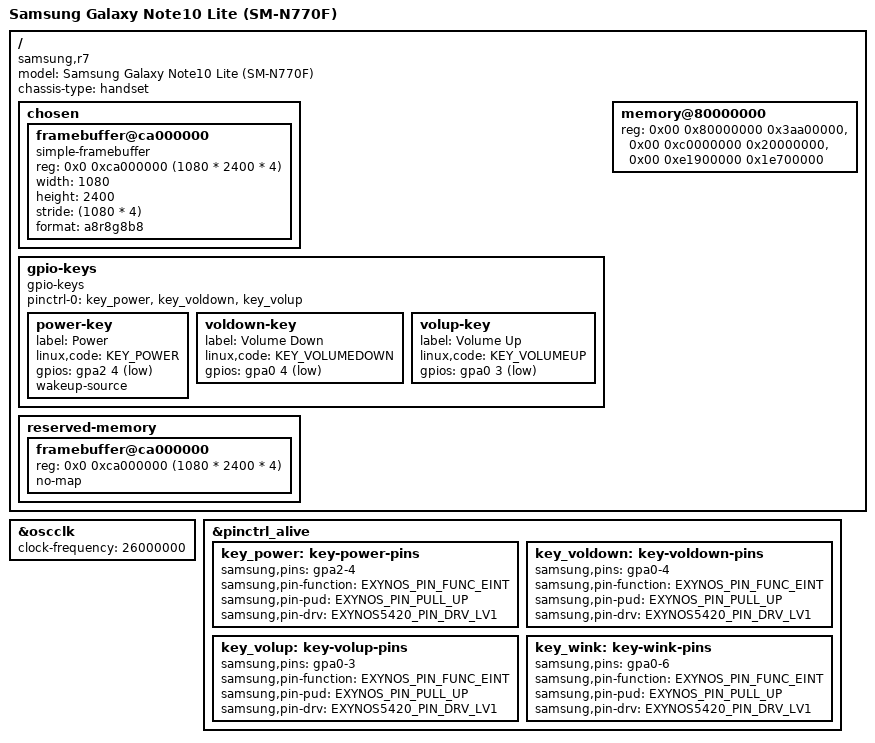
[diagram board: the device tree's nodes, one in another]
// SPDX-License-Identifier: GPL-2.0 OR BSD-3-Clause
/*
 * Samsung Galaxy Note10 Lite (r7/N770F) device tree source
 *
 * Copyright (c) 2024 Markuss Broks <markuss.broks@gmail.com>
 * Copyright (c) 2024 Maksym Holovach <nergzd@nergzd723.xyz>
 * Copyright (c) 2026 Leah <leah@realfx.rocks>
 */

/dts-v1/;
#include "exynos9810.dtsi"
#include <dt-bindings/gpio/gpio.h>
#include <dt-bindings/input/input.h>

/ {
	model = "Samsung Galaxy Note10 Lite (SM-N770F)";
	compatible = "samsung,r7", "samsung,exynos9810";
	chassis-type = "handset";

	chosen {
		#address-cells = <2>;
		#size-cells = <1>;
		ranges;

		framebuffer@ca000000 {
			compatible = "simple-framebuffer";
			reg = <0x0 0xca000000 (1080 * 2400 * 4)>;
			width = <1080>;
			height = <2400>;
			stride = <(1080 * 4)>;
			format = "a8r8g8b8";
		};
	};

	gpio-keys {
		compatible = "gpio-keys";

		pinctrl-0 = <&key_power &key_voldown &key_volup>;
		pinctrl-names = "default";

		power-key {
			label = "Power";
			linux,code = <KEY_POWER>;
			gpios = <&gpa2 4 GPIO_ACTIVE_LOW>;
			wakeup-source;
		};

		voldown-key {
			label = "Volume Down";
			linux,code = <KEY_VOLUMEDOWN>;
			gpios = <&gpa0 4 GPIO_ACTIVE_LOW>;
		};

		volup-key {
			label = "Volume Up";
			linux,code = <KEY_VOLUMEUP>;
			gpios = <&gpa0 3 GPIO_ACTIVE_LOW>;
		};
	};

	memory@80000000 {
		device_type = "memory";
		reg = <0x00 0x80000000 0x3aa00000>,
		      <0x00 0xc0000000 0x20000000>,
		      <0x00 0xe1900000 0x1e700000>;
		/*
		      <0x08 0x80000000 0x80000000>,
		      <0x09 0x00 0x80000000>;
		*/
	};

	reserved-memory {
		#address-cells = <2>;
		#size-cells = <1>;
		ranges;

		framebuffer@ca000000 {
			reg = <0x0 0xca000000 (1080 * 2400 * 4)>;
			no-map;
		};
	};
};

&oscclk {
	clock-frequency = <26000000>;
};

&pinctrl_alive {
	key_power: key-power-pins {
		samsung,pins = "gpa2-4";
		samsung,pin-function = <EXYNOS_PIN_FUNC_EINT>;
		samsung,pin-pud = <EXYNOS_PIN_PULL_UP>;
		samsung,pin-drv = <EXYNOS5420_PIN_DRV_LV1>;
	};

	key_voldown: key-voldown-pins {
		samsung,pins = "gpa0-4";
		samsung,pin-function = <EXYNOS_PIN_FUNC_EINT>;
		samsung,pin-pud = <EXYNOS_PIN_PULL_UP>;
		samsung,pin-drv = <EXYNOS5420_PIN_DRV_LV1>;
	};

	key_volup: key-volup-pins {
		samsung,pins = "gpa0-3";
		samsung,pin-function = <EXYNOS_PIN_FUNC_EINT>;
		samsung,pin-pud = <EXYNOS_PIN_PULL_UP>;
		samsung,pin-drv = <EXYNOS5420_PIN_DRV_LV1>;
	};

	key_wink: key-wink-pins {
		samsung,pins = "gpa0-6";
		samsung,pin-function = <EXYNOS_PIN_FUNC_EINT>;
		samsung,pin-pud = <EXYNOS_PIN_PULL_UP>;
		samsung,pin-drv = <EXYNOS5420_PIN_DRV_LV1>;
	};
};
